# a34m42x register map
Vendor: ABOV Semiconductor Co., Ltd.; File version: 1.0
CPU: CM4 r0p1, little endian, MPU, FPU, VTOR, 4 interrupt priority bits
Registers are 32-bit, read-write, reset 0x0 unless marked. A register's access mark holds for its fields unless they carry their own. Offsets are from the block's base; [hi:lo] are bit positions; {n}, {i} and the like mark numbered series.

## PORTEN — General Port Access Enable
Base 0x40001FF0
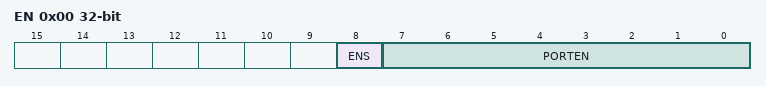
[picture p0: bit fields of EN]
0x00 EN — Port Access Enable Register
  [8] ENS ro — Enable Status Bit
  [7:0] PORTEN wo — Port Access Enable bit, write sequence 0x15, 0x51

## DFMC — DATA FLASH MEMORY CONTROLLER
Base 0x41001000
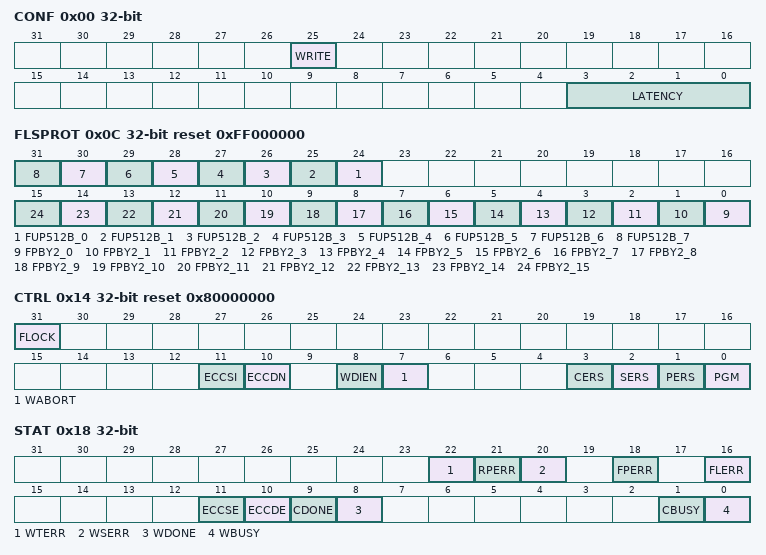
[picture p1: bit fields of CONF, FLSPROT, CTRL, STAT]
0x00 CONF — Data Flash Memory Config Register
  [25] WRITE — Whether to Enable or Disable the Data Flash Write
    0=Disable write; 1=Enable write
  [3:0] LATENCY — Flash Wait Value Bits
0x04 FLSKEY wo — Data Flash Memory Access Key Register
  [31:0] FKEY — Flash Memory Access Key, KEY1(0x01234567) -> KEY2(0x12345678) -> KEY3(0x23456789)
0x0C FLSPROT reset 0xFF000000 — Data Flash Memory Protection Register
  [n+24] FUP512B_{n} (n=0..7) — Flash upper 4KB Unprotection
  [n] FPBY2_{n} (n=0..15) — Flash 2KB Protection
0x14 CTRL reset 0x80000000 — Data Flash Access Control Register
  [31] FLOCK — Flash Memory Lock Bit
  [11] ECCSI — Whether to Enable or Disable the ECC Single Error Interrupt
    0=Disable interrupt; 1=Enable interrupt
  [10] ECCDN — Whether to Enable or Disable the ECC Double Error Non-Maskable Interrupt
    0=Disable interrupt; 1=Enable interrupt
  [8] WDIEN — Whether to Enable or Disable the Write Done Interrupt
    0=Disable interrupt; 1=Enable interrupt
  [7] WABORT — Abort write operation
    0=Disable (No Effect); 1=Enable (Abort write operaton)
  [3] CERS — Flash Memory Bulk(Chip) Erase Mode
    0=Disable bulk erase; 1=Enable bulk erase
  [2] SERS — Flash Memory Sector (2KB) Erase Mode
    0=Disable sector erase; 1=Enable sector erase
  [1] PERS — Flash Memory Page (512 Bytes) Erase Mode
    0=Disable page erase; 1=Enable page erase
  [0] PGM — Flash Memory Write Mode
    0=Disable write mode; 1=Enable write mode
0x18 STAT — Data Flash Access Status Register
  [22] WTERR — Wrtie Timeout Error
  [21] RPERR — Read Protect Error
  [20] WSERR — Write Sequence Error (Cleared by writing a '1' )
  [18] FPERR — Flash Protect Error (Cleared by writing a '1' )
  [16] FLERR — Flash Lock Error (Cleared by writing a '1' )
  [11] ECCSE — ECC Single Error (Cleared by writing a '1' )
  [10] ECCDE — ECC Double Error (Cleared by writing a '1' )
  [9] CDONE — Checksum Done Check (Cleared by writing a '1' )
  [8] WDONE — Write Done Check (Cleared by writing a '1' )
  [1] CBUSY ro — Checksum Busy Check
    0=Not_Busy (Checksum Not Busy); 1=Busy (Checksum Busy)
  [0] WBUSY ro — Write Busy Check
    0=Not_Busy (Checksum Not Busy); 1=Busy (Checksum Busy)
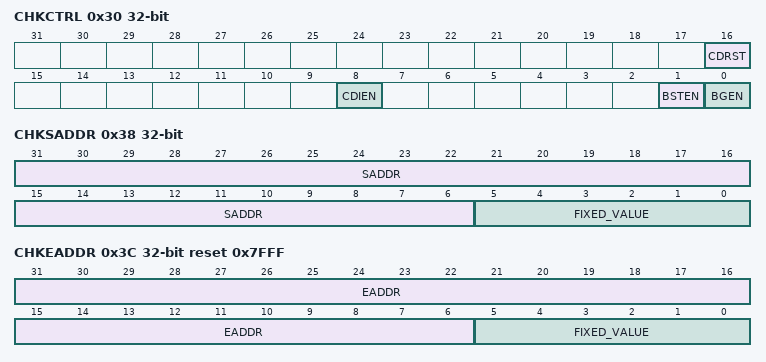
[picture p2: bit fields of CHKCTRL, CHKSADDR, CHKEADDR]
0x30 CHKCTRL — Data Flash Checksum Control Register
  [16] CDRST — Checksum Data Reset (Auto Cleared)
    0=No_Effect; 1=Reset
  [8] CDIEN — Checksum Done Interrupt
    0=Disable interrupt; 1=Enable interrupt
  [1] BSTEN — Burst Mode
    0=Disable burst mode; 1=Enable burst mode
  [0] BGEN — Back Ground Mode
    0=Disable back ground mode; 1=Enable back ground mode
0x34 CHKDOUT ro reset 0xFFFF — Data Flash Checksum Data Output Register
  [15:0] CDOUT — Flash Checksum Data Output bit
0x38 CHKSADDR — Data Flash Checksum Start Address Resgister
  [31:6] SADDR — Flash Checksum Start Address bit
  [5:0] FIXED_VALUE ro — Fixed Vaule
0x3C CHKEADDR reset 0x7FFF — Data Flash Checksum End Address Register
  [31:6] EADDR — Flash Checksum End Address bit
  [5:0] FIXED_VALUE ro
0x40 WTIMEOUT — Data Flash Write Timeout Register
  [31:0] WTIMEOUT — Write timeout count
0x50 ECCEADDR ro — Data Flash ECC Error Address Register
  [31:0] ECCEA — Data Flash ECC Error Address bit
0x54 ECCEDATA ro — Data Flash ECC Error Data Register
  [31:0] ECCED — Data Flash ECC Error Data bit
0x58 ECCPARITY ro — Data Flash ECC Error Parity Register
  [6:0] ECCEP — Data Flash ECC Error Parity
